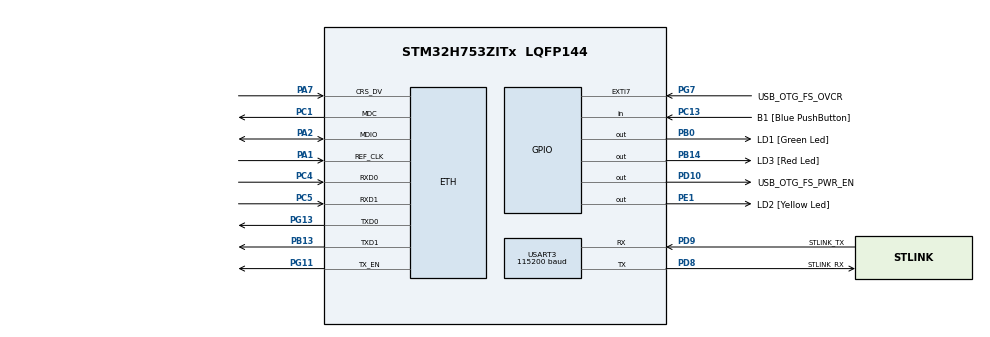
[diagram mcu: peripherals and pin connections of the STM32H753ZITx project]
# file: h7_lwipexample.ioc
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CORTEX_M7.AccessPermission-Cortex_Memory_Protection_Unit_Region0_Settings=MPU_REGION_FULL_ACCESS
CORTEX_M7.BaseAddress-Cortex_Memory_Protection_Unit_Region0_Settings=0x30000000
CORTEX_M7.CPU_DCache=Enabled
CORTEX_M7.CPU_ICache=Enabled
CORTEX_M7.DisableExec-Cortex_Memory_Protection_Unit_Region0_Settings=MPU_INSTRUCTION_ACCESS_ENABLE
CORTEX_M7.Enable-Cortex_Memory_Protection_Unit_Region0_Settings=MPU_REGION_ENABLE
CORTEX_M7.MPU_Control=MPU_PRIVILEGED_DEFAULT
CORTEX_M7.Size-Cortex_Memory_Protection_Unit_Region0_Settings=MPU_REGION_SIZE_256MB
CORTEX_M7.TypeExtField-Cortex_Memory_Protection_Unit_Region0_Settings=MPU_TEX_LEVEL1
ETH.ETH_RX_DESC_CNT=4
ETH.ETH_TX_DESC_CNT=4
ETH.MACAddr=00\:80\:E1\:00\:00\:00
ETH.MediaInterface=HAL_ETH_RMII_MODE
ETH.RxBuffAddress=0x30040200
ETH.RxBuffLen=1524
ETH.RxDescAddress=0x30040000
ETH.TxDescAddress=0x30040060
LWIP.BSP.number=1
LWIP.GATEWAY_ADDRESS=169.254.024.001
LWIP.IP_ADDRESS=169.254.024.157
LWIP.LWIP_DHCP=0
LWIP.LWIP_HTTPD=1
LWIP.LWIP_HTTPD_SSI_BY_FILE_EXTENSION=0
LWIP.MEM_SIZE=16360
LWIP.NETMASK_ADDRESS=255.255.255.000
LWIP.Version=v2.1.2_Cube
LWIP0.BSP.STBoard=false
LWIP0.BSP.api=BSP_COMPONENT_DRIVER
LWIP0.BSP.component=LAN8742
LWIP0.BSP.i2caddr=0
LWIP0.BSP.instance=LAN8742
LWIP0.BSP.name=Driver_PHY
LWIP0.BSP.solution=LAN8742
Mcu.Family=STM32H7
Mcu.Name=STM32H753ZITx
Mcu.Package=LQFP144
NVIC.PriorityGroup=NVIC_PRIORITYGROUP_4
PA1.GPIO_Speed=GPIO_SPEED_FREQ_VERY_HIGH
PA1.Mode=RMII
PA1.Signal=ETH_REF_CLK
PA11.Signal=USB_OTG_FS_DM
PA12.Signal=USB_OTG_FS_DP
PA2.GPIO_Speed=GPIO_SPEED_FREQ_VERY_HIGH
PA2.Mode=RMII
PA2.Signal=ETH_MDIO
PA7.GPIO_Speed=GPIO_SPEED_FREQ_VERY_HIGH
PA7.Mode=RMII
PA7.Signal=ETH_CRS_DV
PA8.Signal=USB_OTG_FS_SOF
PA9.Signal=USB_OTG_FS_VBUS
PB0.GPIO_Label=LD1 [Green Led]
PB0.Signal=GPIO_Output
PB13.GPIO_Speed=GPIO_SPEED_FREQ_VERY_HIGH
PB13.Mode=RMII
PB13.Signal=ETH_TXD1
PB14.GPIO_Label=LD3 [Red Led]
PB14.Signal=GPIO_Output
PC1.GPIO_Speed=GPIO_SPEED_FREQ_LOW
PC1.Mode=RMII
PC1.Signal=ETH_MDC
PC13.GPIO_Label=B1 [Blue PushButton]
PC13.Signal=GPIO_Input
PC14-OSC32_IN\ (OSC32_IN).Mode=LSE-External-Oscillator
PC14-OSC32_IN\ (OSC32_IN).Signal=RCC_OSC32_IN
PC15-OSC32_OUT\ (OSC32_OUT).Mode=LSE-External-Oscillator
PC15-OSC32_OUT\ (OSC32_OUT).Signal=RCC_OSC32_OUT
PC4.GPIO_Speed=GPIO_SPEED_FREQ_VERY_HIGH
PC4.Mode=RMII
PC4.Signal=ETH_RXD0
PC5.GPIO_Speed=GPIO_SPEED_FREQ_VERY_HIGH
PC5.Mode=RMII
PC5.Signal=ETH_RXD1
PD10.GPIO_Label=USB_OTG_FS_PWR_EN
PD10.Signal=GPIO_Output
PD8.GPIO_Label=STLINK_RX
PD8.Mode=Asynchronous
PD8.Signal=USART3_TX
PD9.GPIO_Label=STLINK_TX
PD9.Mode=Asynchronous
PD9.Signal=USART3_RX
PE1.GPIO_Label=LD2 [Yellow Led]
PE1.Signal=GPIO_Output
PG11.GPIO_Speed=GPIO_SPEED_FREQ_VERY_HIGH
PG11.Mode=RMII
PG11.Signal=ETH_TX_EN
PG13.GPIO_Speed=GPIO_SPEED_FREQ_VERY_HIGH
PG13.Mode=RMII
PG13.Signal=ETH_TXD0
PG7.GPIO_Label=USB_OTG_FS_OVCR
PG7.Signal=GPXTI7
PH0-OSC_IN\ (PH0).Mode=HSE-External-Clock-Source
PH0-OSC_IN\ (PH0).Signal=RCC_OSC_IN
PH1-OSC_OUT\ (PH1).Signal=RCC_OSC_OUT
ProjectManager.HeapSize=0x200
ProjectManager.StackSize=0x400
ProjectManager.TargetToolchain=STM32CubeIDE
RCC.ADCFreq_Value=129000000
RCC.APB1Freq_Value=120000000
RCC.APB2Freq_Value=120000000
RCC.APB3Freq_Value=120000000
RCC.APB4Freq_Value=120000000
RCC.CortexFreq_Value=480000000
RCC.D1PPRE=RCC_APB3_DIV2
RCC.D2PPRE1=RCC_APB1_DIV2
RCC.D2PPRE2=RCC_APB2_DIV2
RCC.D3PPRE=RCC_APB4_DIV2
RCC.DIVM1=4
RCC.DIVN1=60
RCC.DIVQ1=4
RCC.HCLKFreq_Value=240000000
RCC.HPRE=RCC_HCLK_DIV2
RCC.HSE_VALUE=8000000
RCC.PLL2FRACN=0
RCC.PLL3FRACN=0
RCC.PLLFRACN=0
RCC.SYSCLKFreq_VALUE=480000000
RCC.SYSCLKSource=RCC_SYSCLKSOURCE_PLLCLK
RCC.USBFreq_Value=240000000
USART3.AutoBaudRateEnableParam=UART_ADVFEATURE_AUTOBAUDRATE_DISABLE
USART3.BaudRate=115200
USART3.ClockPrescaler=PRESCALER_DIV1
USART3.DMADisableonRxErrorParam=ADVFEATURE_DMA_ENABLEONRXERROR
USART3.DataInvertParam=ADVFEATURE_DATAINV_DISABLE
USART3.FIFOMode=FIFOMODE_DISABLE
USART3.MSBFirstParam=ADVFEATURE_MSBFIRST_DISABLE
USART3.Mode=MODE_TX_RX
USART3.OneBitSampling=UART_ONE_BIT_SAMPLE_DISABLE
USART3.OverSampling=UART_OVERSAMPLING_16
USART3.OverrunDisableParam=ADVFEATURE_OVERRUN_ENABLE
USART3.Parity=PARITY_NONE
USART3.RXFIFOThreshold=RXFIFO_THRESHOLD_1EIGHTHFULL
USART3.RxPinLevelInvertParam=ADVFEATURE_RXINV_DISABLE
USART3.StopBits=STOPBITS_1
USART3.SwapParam=ADVFEATURE_SWAP_DISABLE
USART3.TXFIFOThreshold=TXFIFO_THRESHOLD_1EIGHTHFULL
USART3.TxPinLevelInvertParam=ADVFEATURE_TXINV_DISABLE
USART3.VirtualMode-Asynchronous=VM_ASYNC
USART3.WordLength=WORDLENGTH_8B
VP_LWIP_VS_Enabled.Mode=Enabled
VP_RNG_VS_RNG.Mode=RNG_Activate
board=NUCLEO-H753ZI

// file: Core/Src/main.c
/* USER CODE BEGIN Header */
/**
  ******************************************************************************
  * @file           : main.c
  * @brief          : Main program body
  ******************************************************************************
  * @attention
  *
  * <h2><center>&copy; Copyright (c) 2020 STMicroelectronics.
  * All rights reserved.</center></h2>
  *
  * This software component is licensed by ST under Ultimate Liberty license
  * SLA0044, the "License"; You may not use this file except in compliance with
  * the License. You may obtain a copy of the License at:
  *                             www.st.com/SLA0044
  *
  ******************************************************************************
  */
/* USER CODE END Header */
#include "main.h"
#include "lwip.h"

/* USER CODE BEGIN Includes */
#include "lwip/apps/httpd.h"
#include "stm32_udp_server.h"
#include "stm32_udp_client.h"
/* USER CODE END Includes */

RNG_HandleTypeDef hrng;

UART_HandleTypeDef huart3;

/* USER CODE BEGIN PV */
extern volatile uint16_t timerValue;
/* USER CODE END PV */

void SystemClock_Config(void);
static void MPU_Config(void);
static void MX_GPIO_Init(void);
static void MX_USART3_UART_Init(void);
static void MX_RNG_Init(void);

int main(void)
{

  /* MPU Configuration--------------------------------------------------------*/
  MPU_Config();

  /* Enable I-Cache---------------------------------------------------------*/
  SCB_EnableICache();

  /* Enable D-Cache---------------------------------------------------------*/
  SCB_EnableDCache();

  /* MCU Configuration--------------------------------------------------------*/

  /* Reset of all peripherals, Initializes the Flash interface and the Systick. */
  HAL_Init();

  /* Configure the system clock */
  SystemClock_Config();

  /* Initialize all configured peripherals */
  MX_GPIO_Init();
  MX_USART3_UART_Init();
  MX_RNG_Init();
  MX_LWIP_Init();
  /* USER CODE BEGIN 2 */
  //httpd_init();
  //tcp_echoserver_init();

  /* Enable UDP  */
  //udp_client_connect();
  udp_server_init();
//
//  HAL_GPIO_WritePin(GPIOB, LD1_Pin, GPIO_PIN_SET);
//  HAL_GPIO_WritePin(GPIOB, LD3_Pin, GPIO_PIN_SET);

  /* USER CODE END 2 */

  /* Infinite loop */
  while (1) {

    /* USER CODE BEGIN 3 */
	  MX_LWIP_Process();

	  if(timerValue >= 1000)
	  {
		  timerValue = 0;
		  udp_server_send_message();
		  //udp_client_send();
	  }
  }
  /* USER CODE END 3 */
}

void SystemClock_Config(void)
{
  RCC_OscInitTypeDef RCC_OscInitStruct = {0};
  RCC_ClkInitTypeDef RCC_ClkInitStruct = {0};
  RCC_PeriphCLKInitTypeDef PeriphClkInitStruct = {0};

  /** Supply configuration update enable
  */
  HAL_PWREx_ConfigSupply(PWR_LDO_SUPPLY);
  /** Configure the main internal regulator output voltage
  */
  __HAL_PWR_VOLTAGESCALING_CONFIG(PWR_REGULATOR_VOLTAGE_SCALE0);

  while(!__HAL_PWR_GET_FLAG(PWR_FLAG_VOSRDY)) {}
  /** Initializes the RCC Oscillators according to the specified parameters
  * in the RCC_OscInitTypeDef structure.
  */
  RCC_OscInitStruct.OscillatorType = RCC_OSCILLATORTYPE_HSI48|RCC_OSCILLATORTYPE_HSI;
  RCC_OscInitStruct.HSIState = RCC_HSI_DIV1;
  RCC_OscInitStruct.HSICalibrationValue = RCC_HSICALIBRATION_DEFAULT;
  RCC_OscInitStruct.HSI48State = RCC_HSI48_ON;
  RCC_OscInitStruct.PLL.PLLState = RCC_PLL_ON;
  RCC_OscInitStruct.PLL.PLLSource = RCC_PLLSOURCE_HSI;
  RCC_OscInitStruct.PLL.PLLM = 4;
  RCC_OscInitStruct.PLL.PLLN = 60;
  RCC_OscInitStruct.PLL.PLLP = 2;
  RCC_OscInitStruct.PLL.PLLQ = 4;
  RCC_OscInitStruct.PLL.PLLR = 2;
  RCC_OscInitStruct.PLL.PLLRGE = RCC_PLL1VCIRANGE_3;
  RCC_OscInitStruct.PLL.PLLVCOSEL = RCC_PLL1VCOWIDE;
  RCC_OscInitStruct.PLL.PLLFRACN = 0;
  if (HAL_RCC_OscConfig(&RCC_OscInitStruct) != HAL_OK)
  {
    Error_Handler();
  }
  /** Initializes the CPU, AHB and APB buses clocks
  */
  RCC_ClkInitStruct.ClockType = RCC_CLOCKTYPE_HCLK|RCC_CLOCKTYPE_SYSCLK
                              |RCC_CLOCKTYPE_PCLK1|RCC_CLOCKTYPE_PCLK2
                              |RCC_CLOCKTYPE_D3PCLK1|RCC_CLOCKTYPE_D1PCLK1;
  RCC_ClkInitStruct.SYSCLKSource = RCC_SYSCLKSOURCE_PLLCLK;
  RCC_ClkInitStruct.SYSCLKDivider = RCC_SYSCLK_DIV1;
  RCC_ClkInitStruct.AHBCLKDivider = RCC_HCLK_DIV2;
  RCC_ClkInitStruct.APB3CLKDivider = RCC_APB3_DIV2;
  RCC_ClkInitStruct.APB1CLKDivider = RCC_APB1_DIV2;
  RCC_ClkInitStruct.APB2CLKDivider = RCC_APB2_DIV2;
  RCC_ClkInitStruct.APB4CLKDivider = RCC_APB4_DIV2;

  if (HAL_RCC_ClockConfig(&RCC_ClkInitStruct, FLASH_LATENCY_4) != HAL_OK)
  {
    Error_Handler();
  }
  PeriphClkInitStruct.PeriphClockSelection = RCC_PERIPHCLK_USART3|RCC_PERIPHCLK_RNG;
  PeriphClkInitStruct.Usart234578ClockSelection = RCC_USART234578CLKSOURCE_D2PCLK1;
  PeriphClkInitStruct.RngClockSelection = RCC_RNGCLKSOURCE_HSI48;
  if (HAL_RCCEx_PeriphCLKConfig(&PeriphClkInitStruct) != HAL_OK)
  {
    Error_Handler();
  }
}

static void MX_RNG_Init(void)
{

  hrng.Instance = RNG;
  hrng.Init.ClockErrorDetection = RNG_CED_ENABLE;
  if (HAL_RNG_Init(&hrng) != HAL_OK)
  {
    Error_Handler();
  }

}

static void MX_USART3_UART_Init(void)
{

  huart3.Instance = USART3;
  huart3.Init.BaudRate = 115200;
  huart3.Init.WordLength = UART_WORDLENGTH_8B;
  huart3.Init.StopBits = UART_STOPBITS_1;
  huart3.Init.Parity = UART_PARITY_NONE;
  huart3.Init.Mode = UART_MODE_TX_RX;
  huart3.Init.HwFlowCtl = UART_HWCONTROL_NONE;
  huart3.Init.OverSampling = UART_OVERSAMPLING_16;
  huart3.Init.OneBitSampling = UART_ONE_BIT_SAMPLE_DISABLE;
  huart3.Init.ClockPrescaler = UART_PRESCALER_DIV1;
  huart3.AdvancedInit.AdvFeatureInit = UART_ADVFEATURE_NO_INIT;
  if (HAL_UART_Init(&huart3) != HAL_OK)
  {
    Error_Handler();
  }
  if (HAL_UARTEx_SetTxFifoThreshold(&huart3, UART_TXFIFO_THRESHOLD_1_8) != HAL_OK)
  {
    Error_Handler();
  }
  if (HAL_UARTEx_SetRxFifoThreshold(&huart3, UART_RXFIFO_THRESHOLD_1_8) != HAL_OK)
  {
    Error_Handler();
  }
  if (HAL_UARTEx_DisableFifoMode(&huart3) != HAL_OK)
  {
    Error_Handler();
  }

}

static void MX_GPIO_Init(void)
{
  GPIO_InitTypeDef GPIO_InitStruct = {0};

  /* GPIO Ports Clock Enable */
  __HAL_RCC_GPIOC_CLK_ENABLE();
  __HAL_RCC_GPIOH_CLK_ENABLE();
  __HAL_RCC_GPIOA_CLK_ENABLE();
  __HAL_RCC_GPIOB_CLK_ENABLE();
  __HAL_RCC_GPIOD_CLK_ENABLE();
  __HAL_RCC_GPIOG_CLK_ENABLE();
  __HAL_RCC_GPIOE_CLK_ENABLE();

  /*Configure GPIO pin Output Level */
  HAL_GPIO_WritePin(GPIOB, LD1_Pin|LD3_Pin, GPIO_PIN_RESET);

  /*Configure GPIO pin Output Level */
  HAL_GPIO_WritePin(USB_OTG_FS_PWR_EN_GPIO_Port, USB_OTG_FS_PWR_EN_Pin, GPIO_PIN_RESET);

  /*Configure GPIO pin Output Level */
  HAL_GPIO_WritePin(LD2_GPIO_Port, LD2_Pin, GPIO_PIN_RESET);

  /*Configure GPIO pin : B1_Pin */
  GPIO_InitStruct.Pin = B1_Pin;
  GPIO_InitStruct.Mode = GPIO_MODE_INPUT;
  GPIO_InitStruct.Pull = GPIO_NOPULL;
  HAL_GPIO_Init(B1_GPIO_Port, &GPIO_InitStruct);

  /*Configure GPIO pins : LD1_Pin LD3_Pin */
  GPIO_InitStruct.Pin = LD1_Pin|LD3_Pin;
  GPIO_InitStruct.Mode = GPIO_MODE_OUTPUT_PP;
  GPIO_InitStruct.Pull = GPIO_NOPULL;
  GPIO_InitStruct.Speed = GPIO_SPEED_FREQ_LOW;
  HAL_GPIO_Init(GPIOB, &GPIO_InitStruct);

  /*Configure GPIO pin : USB_OTG_FS_PWR_EN_Pin */
  GPIO_InitStruct.Pin = USB_OTG_FS_PWR_EN_Pin;
  GPIO_InitStruct.Mode = GPIO_MODE_OUTPUT_PP;
  GPIO_InitStruct.Pull = GPIO_NOPULL;
  GPIO_InitStruct.Speed = GPIO_SPEED_FREQ_LOW;
  HAL_GPIO_Init(USB_OTG_FS_PWR_EN_GPIO_Port, &GPIO_InitStruct);

  /*Configure GPIO pin : USB_OTG_FS_OVCR_Pin */
  GPIO_InitStruct.Pin = USB_OTG_FS_OVCR_Pin;
  GPIO_InitStruct.Mode = GPIO_MODE_IT_RISING;
  GPIO_InitStruct.Pull = GPIO_NOPULL;
  HAL_GPIO_Init(USB_OTG_FS_OVCR_GPIO_Port, &GPIO_InitStruct);

  /*Configure GPIO pins : PA8 PA11 PA12 */
  GPIO_InitStruct.Pin = GPIO_PIN_8|GPIO_PIN_11|GPIO_PIN_12;
  GPIO_InitStruct.Mode = GPIO_MODE_AF_PP;
  GPIO_InitStruct.Pull = GPIO_NOPULL;
  GPIO_InitStruct.Speed = GPIO_SPEED_FREQ_LOW;
  GPIO_InitStruct.Alternate = GPIO_AF10_OTG1_FS;
  HAL_GPIO_Init(GPIOA, &GPIO_InitStruct);

  /*Configure GPIO pin : LD2_Pin */
  GPIO_InitStruct.Pin = LD2_Pin;
  GPIO_InitStruct.Mode = GPIO_MODE_OUTPUT_PP;
  GPIO_InitStruct.Pull = GPIO_NOPULL;
  GPIO_InitStruct.Speed = GPIO_SPEED_FREQ_LOW;
  HAL_GPIO_Init(LD2_GPIO_Port, &GPIO_InitStruct);

}

/* MPU Configuration */

void MPU_Config(void)
{
  MPU_Region_InitTypeDef MPU_InitStruct = {0};

  /* Disables the MPU */
  HAL_MPU_Disable();
  /** Initializes and configures the Region and the memory to be protected
  */
  MPU_InitStruct.Enable = MPU_REGION_ENABLE;
  MPU_InitStruct.Number = MPU_REGION_NUMBER0;
  MPU_InitStruct.BaseAddress = 0x30000000;
  MPU_InitStruct.Size = MPU_REGION_SIZE_256MB;
  MPU_InitStruct.SubRegionDisable = 0x0;
  MPU_InitStruct.TypeExtField = MPU_TEX_LEVEL1;
  MPU_InitStruct.AccessPermission = MPU_REGION_FULL_ACCESS;
  MPU_InitStruct.DisableExec = MPU_INSTRUCTION_ACCESS_ENABLE;
  MPU_InitStruct.IsShareable = MPU_ACCESS_NOT_SHAREABLE;
  MPU_InitStruct.IsCacheable = MPU_ACCESS_NOT_CACHEABLE;
  MPU_InitStruct.IsBufferable = MPU_ACCESS_NOT_BUFFERABLE;

  HAL_MPU_ConfigRegion(&MPU_InitStruct);
  /* Enables the MPU */
  HAL_MPU_Enable(MPU_PRIVILEGED_DEFAULT);

}

void Error_Handler(void)
{
  __disable_irq();
  while (1)
  {
  }
}

/************************ (C) COPYRIGHT STMicroelectronics *****END OF FILE****/
